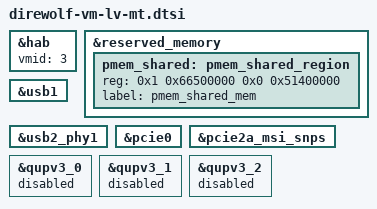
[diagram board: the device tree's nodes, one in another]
&hab {
	vmid = <3>;
};

&reserved_memory {
	pmem_shared: pmem_shared_region {
		reg = <0x1 0x66500000 0x0 0x51400000>;
		label = "pmem_shared_mem";
	};
};

#include "display/quin-vm-display-lxc.dtsi"

&usb1 {
	status = "okay";
};

&usb2_phy1 {
	status = "okay";
};

&pcie0 {
	status = "okay";
};

&pcie2a_msi_snps {
	status = "okay";
};

&qupv3_0 {
	status = "disabled";
};

&qupv3_1 {
	status = "disabled";
};

&qupv3_2 {
	status = "disabled";
};
